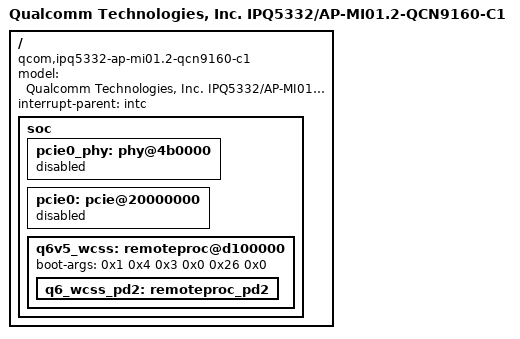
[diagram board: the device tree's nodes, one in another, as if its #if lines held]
// SPDX-License-Identifier: (GPL-2.0+ OR BSD-3-Clause)
/*
 * IPQ5332 AP-MI01.2-QCN9160-C1 board device tree source
 *
 * Copyright (c) 2020-2021 The Linux Foundation. All rights reserved.
 * Copyright (c) 2022 Qualcomm Innovation Center, Inc. All rights reserved.
 */

/dts-v1/;

#ifdef __IPQ_MEM_PROFILE_512_MB__
#include "ipq5332-512MB-memory.dtsi"
#else
#include "ipq5332-default-memory.dtsi"
#endif

#include "ipq5332-mi01.2.dtsi"

/ {
	#address-cells = <0x2>;
	#size-cells = <0x2>;
	model = "Qualcomm Technologies, Inc. IPQ5332/AP-MI01.2-QCN9160-C1";
	compatible = "qcom,ipq5332-ap-mi01.2-qcn9160-c1", "qcom,ipq5332";
	interrupt-parent = <&intc>;

	soc {
		pcie0_phy: phy@4b0000{
			status = "disabled";
		};

		pcie0: pcie@20000000 {
			status = "disabled";
		};

		q6v5_wcss: remoteproc@d100000 {
			boot-args = <0x1 0x4 0x3 0x0 0x26 0x0>;
			q6_wcss_pd2: remoteproc_pd2 {
				status = "ok";
			};
		};
	};
};
